# STM32L100xBA register map
File version: 1.0
Registers are 32-bit, read-write, reset 0x0 unless marked. A register's access mark holds for its fields unless they carry their own. Offsets are from the block's base; [hi:lo] are bit positions; {n}, {i} and the like mark numbered series.

## I2C1 — Inter-integrated Circuit Interface
Base 0x40005400
Same registers: I2C2 0x40005800
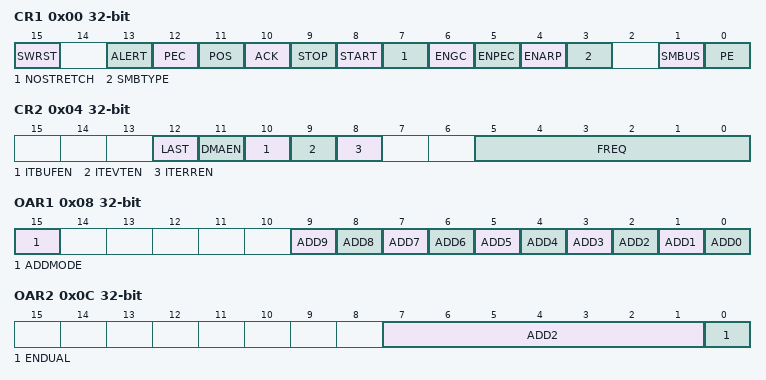
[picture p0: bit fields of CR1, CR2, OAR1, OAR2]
0x00 CR1 — I2C Control register 1
  [15] SWRST — Software Reset
  [13] ALERT — SMBus Alert
  [12] PEC — Packet Error Checking
  [11] POS — Acknowledge/PEC Position (for data reception)
  [10] ACK — Acknowledge Enable
    1=ACK (ACK is sent after current received byte.); 0=NACK (NACK is sent after current received byte.)
  [9] STOP — Stop Generation
  [8] START — Start Generation
  [7] NOSTRETCH — Clock Stretching Disable (Slave mode)
  [6] ENGC — General Call Enable
  [5] ENPEC — PEC Enable
  [4] ENARP — ARP Enable
  [3] SMBTYPE — SMBus Type
  [1] SMBUS — SMBus Mode
  [0] PE — Peripheral Enable
0x04 CR2 — I2C Control register 2
  [12] LAST — DMA Last Transfer
  [11] DMAEN — DMA Requests Enable
  [10] ITBUFEN — Buffer Interrupt Enable
  [9] ITEVTEN — Event Interrupt Enable
  [8] ITERREN — Error Interrupt Enable
  [5:0] FREQ — FREQ[5:0] bits (Peripheral Clock Frequency)
0x08 OAR1 — I2C Own address register 1
  [15] ADDMODE — Addressing Mode (Slave mode)
  [n] ADD{n} (n=0..9) — Bit {n}
0x0C OAR2 — I2C Own address register 2
  [7:1] ADD2 — Interface address
  [0] ENDUAL — Dual addressing mode enable
0x10 DR — I2C Data register
  [7:0] DR — 8-bit Data Register
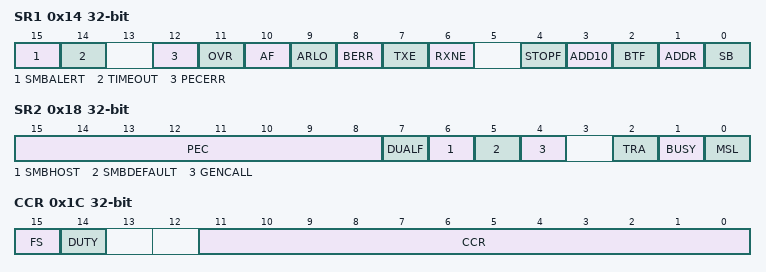
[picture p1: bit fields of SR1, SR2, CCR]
0x14 SR1 — I2C Status register 1
  [15] SMBALERT — SMBus Alert
  [14] TIMEOUT — Timeout or Tlow Error
  [12] PECERR — PEC Error in reception
  [11] OVR — Overrun/Underrun
  [10] AF — Acknowledge Failure
  [9] ARLO — Arbitration Lost (master mode)
  [8] BERR — Bus Error
  [7] TXE — Data Register Empty (transmitters)
  [6] RXNE — Data Register not Empty (receivers)
  [4] STOPF — Stop detection (Slave mode)
  [3] ADD10 — 10-bit header sent (Master mode)
  [2] BTF — Byte Transfer Finished
  [1] ADDR — Address sent (master mode)/matched (slave mode)
  [0] SB — Start Bit (Master mode)
0x18 SR2 — I2C Status register 2
  [15:8] PEC — Packet Error Checking Register
  [7] DUALF — Dual Flag (Slave mode)
  [6] SMBHOST — SMBus Host Header (Slave mode)
  [5] SMBDEFAULT — SMBus Device Default Address (Slave mode)
  [4] GENCALL — General Call Address (Slave mode)
  [2] TRA — Transmitter/Receiver
    1=WRITE (Bus is in write transfer); 0=READ (Bus is in read transfer)
  [1] BUSY — Bus Busy
  [0] MSL — Master/Slave
0x1C CCR — I2C Clock control register
  [15] FS — I2C Master Mode Selection
    0=STANDARD_MODE (Master clock speed range is standard mode); 1=FAST_MODE (Master clock speed range is fast mode)
  [14] DUTY — Fast Mode Duty Cycle
    0=DUTYCYCLE_2 (I2C fast mode Tlow/Thigh = 2); 1=DUTYCYCLE_16_9 (I2C fast mode Tlow/Thigh = 16/9)
  [11:0] CCR — Clock Control Register in Fast/Standard mode (Master mode)
0x20 TRISE — I2C TRISE register
  [5:0] TRISE — Maximum Rise Time in Fast/Standard mode (Master mode)

## USB — Universal Serial Bus Full Speed Device
Base 0x40005C00
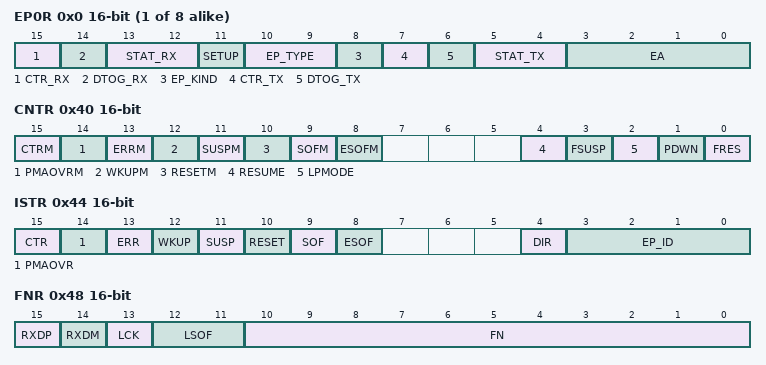
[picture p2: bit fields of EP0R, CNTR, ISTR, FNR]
{0x0+4i} EP{i}R 16-bit (i=0..7) — USB Endpoint {i} register
  [15] CTR_RX — Correct Transfer for reception
  [14] DTOG_RX — Data Toggle, for reception transfers
  [13:12] STAT_RX — STAT_RX[1:0] bits (Status bits, for reception transfers)
  [11] SETUP — Setup transaction completed
  [10:9] EP_TYPE — EP_TYPE[1:0] bits (Endpoint type)
  [8] EP_KIND — Endpoint Kind
  [7] CTR_TX — Correct Transfer for transmission
  [6] DTOG_TX — Data Toggle, for transmission transfers
  [5:4] STAT_TX — STAT_TX[1:0] bits (Status bits, for transmission transfers)
  [3:0] EA — Endpoint Address
0x40 CNTR 16-bit — Control register
  [15] CTRM — Correct Transfer Interrupt Mask
  [14] PMAOVRM — Packet Memory Area Over / Underrun Interrupt Mask
  [13] ERRM — Error Interrupt Mask
  [12] WKUPM — Wakeup Interrupt Mask
  [11] SUSPM — Suspend mode Interrupt Mask
  [10] RESETM — RESET Interrupt Mask
  [9] SOFM — Start Of Frame Interrupt Mask
  [8] ESOFM — Expected Start Of Frame Interrupt Mask
  [4] RESUME — Resume request
  [3] FSUSP — Force suspend
  [2] LPMODE — Low-power mode
  [1] PDWN — Power down
  [0] FRES — Force USB Reset
0x44 ISTR 16-bit — Interrupt status register
  [15] CTR — Correct Transfer
  [14] PMAOVR — Packet Memory Area Over / Underrun
  [13] ERR — Error
  [12] WKUP — Wake up
  [11] SUSP — Suspend mode request
  [10] RESET — USB RESET request
  [9] SOF — Start Of Frame
  [8] ESOF — Expected Start Of Frame
  [4] DIR — Direction of transaction
  [3:0] EP_ID — Endpoint Identifier
0x48 FNR 16-bit — Frame number register
  [15] RXDP — Receive Data + Line Status
  [14] RXDM — Receive Data - Line Status
  [13] LCK — Locked
  [12:11] LSOF — Lost SOF
  [10:0] FN — Frame Number
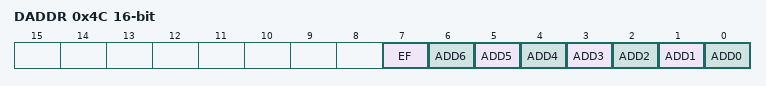
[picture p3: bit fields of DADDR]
0x4C DADDR 16-bit — Device address register
  [7] EF — Enable Function
  [n] ADD{n} (n=0..6) — Bit {n}
0x50 BTABLE 16-bit — Buffer Table address register
  [15:3] BTABLE — Buffer Table
